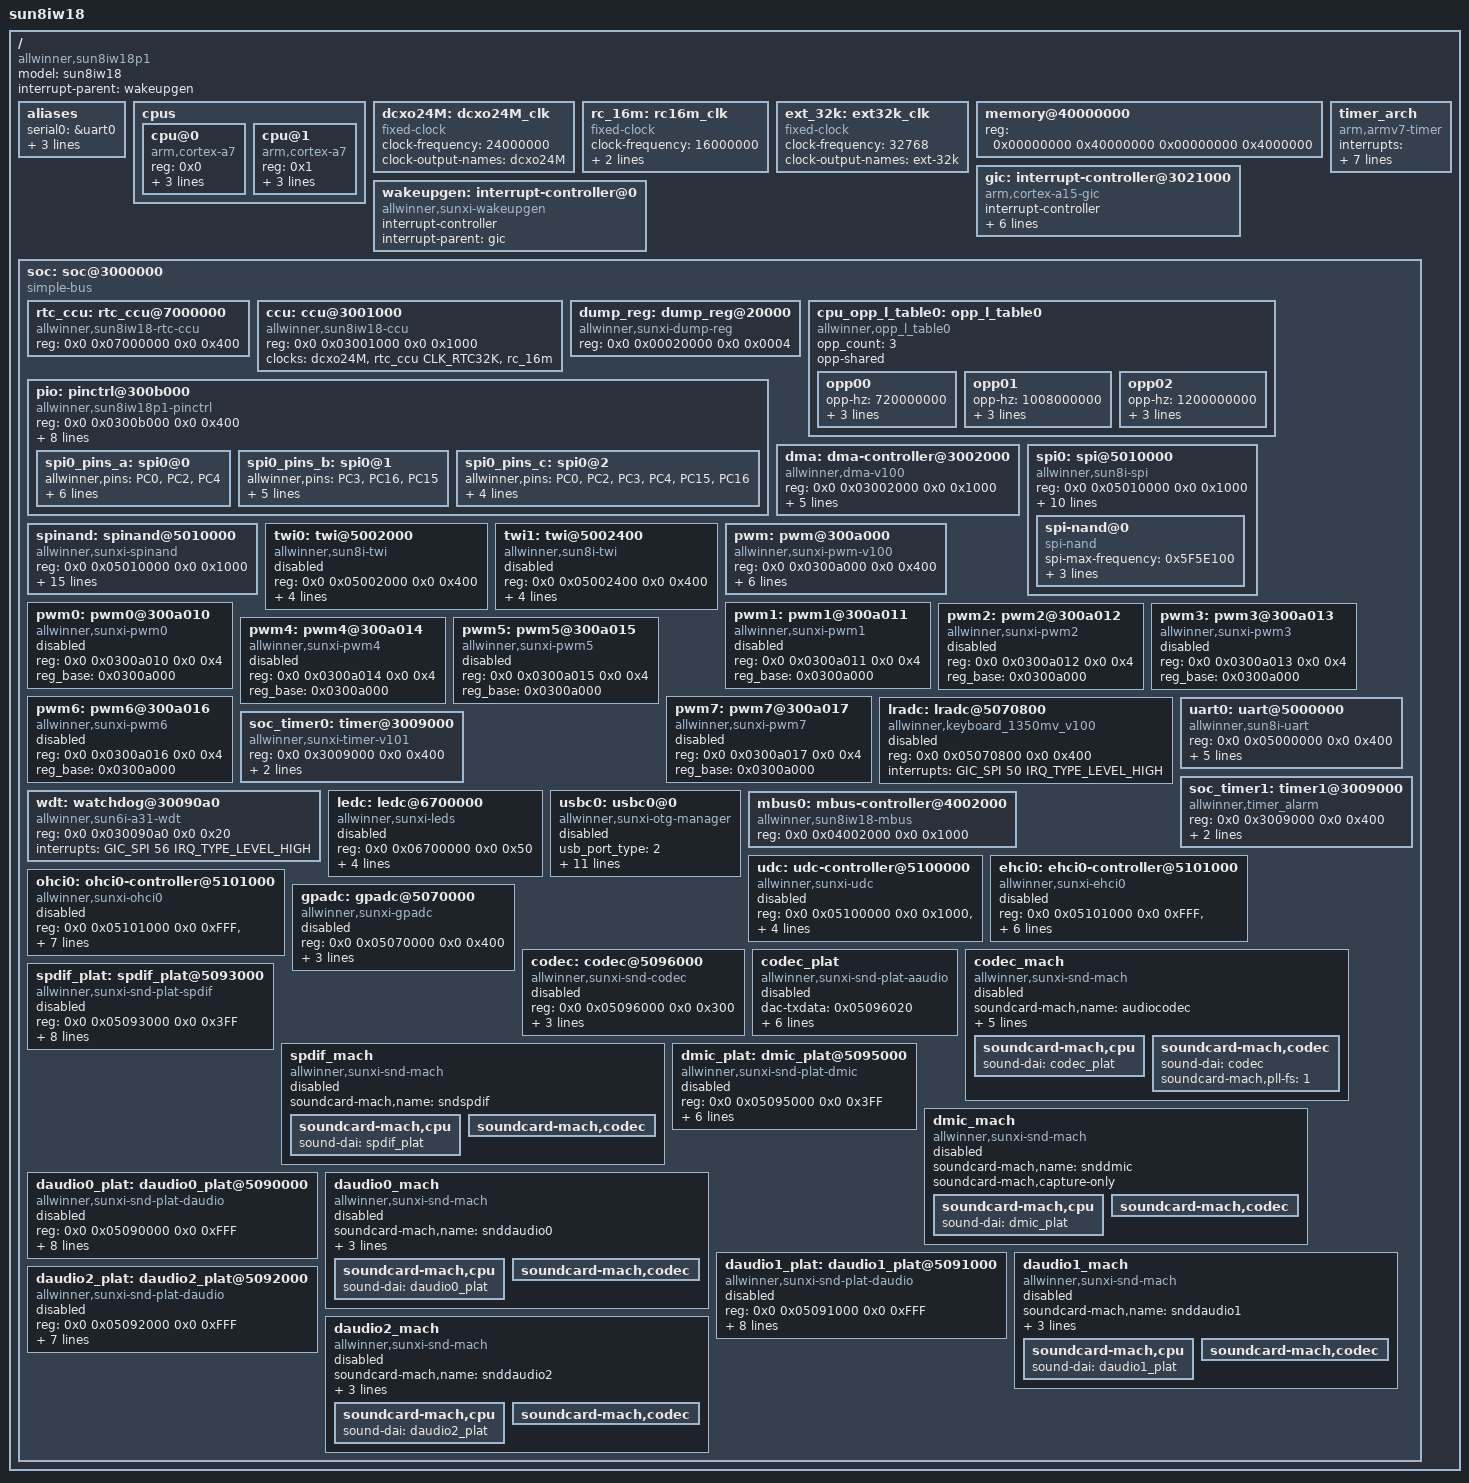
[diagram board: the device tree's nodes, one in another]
/*
 * Allwinner Technology CO., Ltd. sun8iw18p1 platform
 *
 * modify base on juno.dts
 */

/* optee used 4M: SHM 1M, OS 1M, TA 6M*/
/memreserve/ 0x41800000 0x00800000;

#include <dt-bindings/interrupt-controller/arm-gic.h>
#include <dt-bindings/gpio/gpio.h>
#include <dt-bindings/gpio/sun4i-gpio.h>
#include <dt-bindings/clock/sun8iw18-ccu.h>
#include <dt-bindings/reset/sun8iw18-ccu.h>
#include <dt-bindings/clock/sun8iw18-rtc.h>

/ {
	model = "sun8iw18";
	compatible = "allwinner,sun8iw18p1";
	interrupt-parent = <&wakeupgen>;
	#address-cells = <2>;
	#size-cells = <2>;

	aliases {
		serial0 = &uart0;
		pio = &pio;
		spi0 = &spi0;
		spinand = &spinand;
	};

	cpus {
		#address-cells = <1>;
		#size-cells = <0>;

		cpu@0 {
			device_type = "cpu";
			compatible = "arm,cortex-a7","arm,armv7";
			reg = <0x0>;
			enable-method = "psci";
			clocks = <&ccu CLK_CPUX>;
			clock-names = "cpu";
			operating-points-v2 = <&cpu_opp_l_table0>;
		};

		cpu@1 {
			device_type = "cpu";
			compatible = "arm,cortex-a7","arm,armv7";
			reg = <0x1>;
			enable-method = "psci";
			clocks = <&ccu CLK_CPUX>;
			clock-names = "cpu";
			operating-points-v2 = <&cpu_opp_l_table0>;
		};
	};

	dcxo24M: dcxo24M_clk {
		#clock-cells = <0>;
		compatible = "fixed-clock";
		clock-frequency = <24000000>;
		clock-output-names = "dcxo24M";
	};

	rc_16m: rc16m_clk {
		#clock-cells = <0>;
		compatible = "fixed-clock";
		clock-frequency = <16000000>;
		clock-accuracy = <300000000>;
		clock-output-names = "rc-16m";
	};

	ext_32k: ext32k_clk {
		#clock-cells = <0>;
		compatible = "fixed-clock";
		clock-frequency = <32768>;
		clock-output-names = "ext-32k";
	};

	memory@40000000 {
		device_type = "memory";
		reg = <0x00000000 0x40000000 0x00000000 0x4000000>;
	};

	gic: interrupt-controller@3021000 {
		compatible = "arm,cortex-a15-gic", "arm,cortex-a9-gic";
		#interrupt-cells = <3>;
		#address-cells = <0>;
		device_type = "gic";
		interrupt-controller;
		reg = <0x0 0x03021000 0 0x1000>, /* GIC Dist */
		      <0x0 0x03022000 0 0x2000>, /* GIC CPU */
		      <0x0 0x03024000 0 0x2000>, /* GIC VCPU Control */
		      <0x0 0x03026000 0 0x2000>; /* GIC VCPU */
		interrupts = <GIC_PPI 9 0xf04>; /* GIC Maintenence IRQ */
		interrupt-parent = <&gic>;
	};

	wakeupgen: interrupt-controller@0 {
		compatible = "allwinner,sunxi-wakeupgen";
		interrupt-controller;
		#interrupt-cells = <3>;
		interrupt-parent = <&gic>;
	};

	timer_arch {
		compatible = "arm,armv7-timer";
		interrupts = <GIC_PPI 13 (GIC_CPU_MASK_SIMPLE(4) | IRQ_TYPE_LEVEL_LOW)>,
					<GIC_PPI 14 (GIC_CPU_MASK_SIMPLE(4) | IRQ_TYPE_LEVEL_LOW)>,
					<GIC_PPI 11 (GIC_CPU_MASK_SIMPLE(4) | IRQ_TYPE_LEVEL_LOW)>,
					<GIC_PPI 10 (GIC_CPU_MASK_SIMPLE(4) | IRQ_TYPE_LEVEL_LOW)>;
		clock-frequency = <24000000>;
		arm,cpu-registers-not-fw-configured;
		interrupt-parent = <&gic>;
	};

	soc: soc@3000000 {
		compatible = "simple-bus";
		#address-cells = <2>;
		#size-cells = <2>;
		ranges;
		device_type = "soc";

		rtc_ccu: rtc_ccu@7000000 {
			compatible = "allwinner,sun8iw18-rtc-ccu";
			reg = <0x0 0x07000000 0x0 0x400>;
			#clock-cells = <1>;
			#reset-cells = <1>;
		};

		ccu: ccu@3001000 {
			compatible = "allwinner,sun8iw18-ccu";
			reg = <0x0 0x03001000 0x0 0x1000>;
			clocks = <&dcxo24M>, <&rtc_ccu CLK_RTC32K>, <&rc_16m>;
			clock-names = "hosc", "losc", "iosc";
			#clock-cells = <1>;
			#reset-cells = <1>;
		};

		dump_reg: dump_reg@20000 {
			compatible = "allwinner,sunxi-dump-reg";
			reg = <0x0 0x00020000 0x0 0x0004>;
		};

		cpu_opp_l_table0: opp_l_table0 {
			/* compatible = "operating-points-v2"; */
			compatible = "allwinner,opp_l_table0";
			opp_count = <3>;
			opp-shared;

			opp00 {
				opp-hz = /bits/ 64 <720000000>;
				opp-microvolt = <820000>;
				axi-bus-divide-ratio = <3>;
				clock-latency-ns = <2000000>;
			};

			opp01 {
				opp-hz = /bits/ 64 <1008000000>;
				opp-microvolt = <900000>;
				axi-bus-divide-ratio = <3>;
				clock-latency-ns = <2000000>;
			};

			opp02 {
				opp-hz = /bits/ 64 <1200000000>;
				opp-microvolt = <1000000>;
				axi-bus-divide-ratio = <3>;
				clock-latency-ns = <2000000>;
			};

		};
		pio: pinctrl@300b000 {
			compatible = "allwinner,sun8iw18p1-pinctrl";
			reg = <0x0 0x0300b000 0x0 0x400>;
			interrupts = <GIC_SPI 43 IRQ_TYPE_LEVEL_HIGH>,
				     <GIC_SPI 44 IRQ_TYPE_LEVEL_HIGH>,
				     <GIC_SPI 46 IRQ_TYPE_LEVEL_HIGH>,
				     <GIC_SPI 47 IRQ_TYPE_LEVEL_HIGH>;
			device_type = "pio";
			clocks = <&ccu CLK_APB1>, <&dcxo24M>, <&rtc_ccu CLK_RTC32K>;
			clock-names = "apb", "hosc", "bus";
			gpio-controller;
			interrupt-controller;
			#interrupt-cells = <3>;
			#size-cells = <0>;
			#gpio-cells = <3>;

			spi0_pins_a: spi0@0 {
				allwinner,pins = "PC0", "PC2", "PC4";
				allwinner,pname = "spi0_sclk", "spi0_mosi",
						  "spi0_miso";
				allwinner,function = "spi0";
				allwinner,muxsel = <4>;
				allwinner,drive = <1>;
				allwinner,pull = <0>;
			};

			spi0_pins_b: spi0@1 {
				allwinner,pins = "PC3", "PC16", "PC15";
				allwinner,pname = "spi0_cs0", "spi0_hold",
						  "spi0_wp";
				allwinner,function = "spi0";
				allwinner,muxsel = <4>;
				allwinner,drive = <1>;
				allwinner,pull = <1>; 	// only CS should be pulled up
			};

			spi0_pins_c: spi0@2 {
				allwinner,pins = "PC0", "PC2", "PC3", "PC4",
						 "PC15", "PC16";
				allwinner,function = "io_disabled";
				allwinner,muxsel = <7>;
				allwinner,drive = <1>;
				allwinner,pull = <0>;
			};


		};

		dma:dma-controller@3002000 {
			compatible = "allwinner,dma-v100";
			reg = <0x0 0x03002000 0x0 0x1000>;
			interrupts = <GIC_SPI 34 IRQ_TYPE_LEVEL_HIGH>;
			clocks = <&ccu CLK_BUS_DMA>, <&ccu CLK_MBUS_DMA>;
			clock-names = "bus", "mbus";
			resets = <&ccu RST_BUS_DMA>;
			dma-channels = <10>;
			dma-requests = <47>;
			#dma-cells = <1>;
		};

		spi0: spi@5010000 {
			#address-cells = <1>;
			#size-cells = <0>;
			compatible = "allwinner,sun8i-spi";
			device_type = "spi0";
			reg = <0x0 0x05010000 0x0 0x1000>;
			interrupts = <GIC_SPI 81 IRQ_TYPE_LEVEL_HIGH>;
			clocks = <&ccu CLK_PLL_PERI0_1X>, <&ccu CLK_SPI0>, <&ccu CLK_BUS_SPI0>;
			clock-names = "pll", "mod", "bus";
			resets = <&ccu RST_BUS_SPI0>;
			clock-frequency = <100000000>;
			pinctrl-names = "default", "sleep";
			pinctrl-0 = <&spi0_pins_a &spi0_pins_b>;
			pinctrl-1 = <&spi0_pins_c>;
			spi0_cs_number = <2>;
			spi0_cs_bitmap = <3>;
                        dmas = <&dma 22>, <&dma 22>;
			dma-names = "tx", "rx";
			status = "okay";
			spi-nand@0 {
				compatible = "spi-nand";
				spi-max-frequency=<0x5F5E100>;
				reg = <0x0>;
				spi-rx-bus-width=<0x02>;
				spi-tx-bus-width=<0x01>;
				status = "okay";
			};
		};

		spinand: spinand@5010000 {
			compatible = "allwinner,sunxi-spinand", "allwinner,sunxi-mtd-spinand";
			device_type = "spinand";
			reg = <0x0 0x05010000 0x0 0x1000>;
			interrupts = <GIC_SPI 81 IRQ_TYPE_LEVEL_HIGH>;
			clocks = <&ccu CLK_PLL_PERI0_1X>, <&ccu CLK_SPI0>;
			pinctrl-names = "default", "sleep";
			pinctrl-0 = <&spi0_pins_a &spi0_pins_b>;
			pinctrl-1 = <&spi0_pins_c>;
			nand0_regulator1 = "vcc-nand";
			nand0_regulator2 = "none";
			nand0_cache_level = <0x55aaaa55>;
			nand0_flush_cache_num = <0x55aaaa55>;
			nand0_capacity_level = <0x55aaaa55>;
			nand0_id_number_ctl = <0x55aaaa55>;
			nand0_print_level = <0x55aaaa55>;
			nand0_p0 = <0x55aaaa55>;
			nand0_p1 = <0x55aaaa55>;
			nand0_p2 = <0x55aaaa55>;
			nand0_p3 = <0x55aaaa55>;
			status = "okay";
		};

		twi0: twi@5002000 {
			#address-cells = <1>;
			#size-cells = <0>;
			compatible = "allwinner,sun8i-twi";
			device_type = "twi0";
			reg = <0x0 0x05002000 0x0 0x400>;
			interrupts = <GIC_SPI 70 IRQ_TYPE_LEVEL_HIGH>;
			clocks = <&ccu CLK_TWI0>;
			clock-names = "bus";
			resets = <&ccu RST_BUS_TWI0>;
			dmas = <&dma 45>, <&dma 45>;
			dma-names = "tx", "rx";
			status = "disabled";
		};

		twi1: twi@5002400 {
			#address-cells = <1>;
			#size-cells = <0>;
			compatible = "allwinner,sun8i-twi";
			device_type = "twi1";
			reg = <0x0 0x05002400 0x0 0x400>;
			interrupts = <GIC_SPI 71 IRQ_TYPE_LEVEL_HIGH>;
			clocks = <&ccu CLK_TWI1>;
			clock-names = "bus";
			resets = <&ccu RST_BUS_TWI1>;
			dmas = <&dma 46>, <&dma 46>;
			dma-names = "tx", "rx";
			status = "disabled";
		};

		pwm: pwm@300a000 {
			#pwm-cells = <0x3>;
			compatible = "allwinner,sunxi-pwm-v100";
			reg = <0x0 0x0300a000 0x0 0x400>;
			clocks = <&ccu CLK_PWM>;
			resets = <&ccu RST_BUS_PWM>;
			pwm-number = <8>;
			pwm-base = <0x0>;
			sunxi-pwms = <&pwm0>, <&pwm1>, <&pwm2>, <&pwm3>, <&pwm4>,
			       <&pwm5>, <&pwm6>, <&pwm7>;
		};

		pwm0: pwm0@300a010 {
			compatible = "allwinner,sunxi-pwm0";
			reg = <0x0 0x0300a010 0x0 0x4>;
			reg_base = <0x0300a000>;
			status = "disabled";
		};

		pwm1: pwm1@300a011 {
			compatible = "allwinner,sunxi-pwm1";
			reg = <0x0 0x0300a011 0x0 0x4>;
			reg_base = <0x0300a000>;
			status = "disabled";
		};

		pwm2: pwm2@300a012 {
			compatible = "allwinner,sunxi-pwm2";
			reg = <0x0 0x0300a012 0x0 0x4>;
			reg_base = <0x0300a000>;
			status = "disabled";
		};

		pwm3: pwm3@300a013 {
			compatible = "allwinner,sunxi-pwm3";
			reg = <0x0 0x0300a013 0x0 0x4>;
			reg_base = <0x0300a000>;
			status = "disabled";
		};

		pwm4: pwm4@300a014 {
			compatible = "allwinner,sunxi-pwm4";
			reg = <0x0 0x0300a014 0x0 0x4>;
			reg_base = <0x0300a000>;
			status = "disabled";
		};

		pwm5: pwm5@300a015 {
			compatible = "allwinner,sunxi-pwm5";
			reg = <0x0 0x0300a015 0x0 0x4>;
			reg_base = <0x0300a000>;
			status = "disabled";
		};

		pwm6: pwm6@300a016 {
			compatible = "allwinner,sunxi-pwm6";
			reg = <0x0 0x0300a016 0x0 0x4>;
			reg_base = <0x0300a000>;
			status = "disabled";
		};

		pwm7: pwm7@300a017 {
			compatible = "allwinner,sunxi-pwm7";
			reg = <0x0 0x0300a017 0x0 0x4>;
			reg_base = <0x0300a000>;
			status = "disabled";
		};

		lradc: lradc@5070800 {
			compatible = "allwinner,keyboard_1350mv_v100";
			reg = <0x0 0x05070800 0x0 0x400>;
			interrupts = <GIC_SPI 50 IRQ_TYPE_LEVEL_HIGH>;
			status = "disabled";
		};

		uart0: uart@5000000 {
			compatible = "allwinner,sun8i-uart";
			device_type = "uart0";
			reg = <0x0 0x05000000 0x0 0x400>;
			interrupts = <GIC_SPI 76 IRQ_TYPE_LEVEL_HIGH>;
			clocks = <&ccu CLK_BUS_UART0>;
			resets = <&ccu RST_BUS_UART0>;
			uart0_port = <0>;
			uart0_type = <2>;
			status = "okay";
		};

		soc_timer0: timer@3009000 {
			compatible = "allwinner,sunxi-timer-v101";
			device_type = "soc_timer";
			reg = <0x0 0x3009000 0x0 0x400>;
			interrupts = <GIC_SPI 85 IRQ_TYPE_LEVEL_HIGH>;
			clocks = <&dcxo24M>, <&ccu CLK_RTC32K>;
		};

		soc_timer1: timer1@3009000 {
			compatible = "allwinner,timer_alarm";
			reg = <0x0 0x3009000 0x0 0x400>;
			interrupts = <GIC_SPI 86 IRQ_TYPE_LEVEL_HIGH>;
			wakeup-source;
			status = "okay";
		};

		wdt: watchdog@30090a0 {
			compatible = "allwinner,sun6i-a31-wdt";
			reg = <0x0 0x030090a0 0x0 0x20>;
			interrupts = <GIC_SPI 56 IRQ_TYPE_LEVEL_HIGH>;
			status = "okay";
		};

		ledc: ledc@6700000 {
			#address-cells = <1>;
			#size-cells = <0>;
			compatible = "allwinner,sunxi-leds";
			reg = <0x0 0x06700000 0x0 0x50>;
			interrupts = <GIC_SPI 60 IRQ_TYPE_LEVEL_HIGH>;
			interrupt-names = "ledcirq";
			clocks = <&ccu CLK_LEDC>, <&ccu CLK_BUS_LEDC>;
			clock-names = "clk_ledc", "clk_cpuapb";
			resets = <&ccu RST_BUS_LEDC>;
			reset-names = "ledc_reset";
			dmas = <&dma 43>, <&dma 43>;
			dma-names = "rx", "tx";
			status = "disabled";
		};

		usbc0:usbc0@0 {
			device_type = "usbc0";
			compatible = "allwinner,sunxi-otg-manager";
			usb_port_type = <2>;
			usb_detect_type = <1>;
			usb_detect_mode = <0>;
			usb_id_gpio;
			usb_det_vbus_gpio;
			usb_drv_vbus_gpio;
			usb_regulator_io = "nocare";
			usb_wakeup_suspend = <0>;
			usb_luns = <3>;
			usb_serial_unique = <0>;
			usb_serial_number = "20080411";
			rndis_wceis = <1>;
			status = "disabled";
		};

		mbus0: mbus-controller@4002000 {
			compatible = "allwinner,sun8iw18-mbus";
			reg = <0x0 0x04002000 0x0 0x1000>;
			#mbus-cells = <1>;
			status = "okay";
		};

		udc:udc-controller@5100000 {
			compatible = "allwinner,sunxi-udc";
			reg = <0x0 0x05100000 0x0 0x1000>, /*udc base*/
			      <0x0 0x00000000 0x0 0x100>; /*sram base*/
			interrupts = <GIC_SPI 37 IRQ_TYPE_LEVEL_HIGH>;
			clocks = <&ccu CLK_USBOTG>, <&ccu CLK_USBPHY0>;
			clock-names = "bus_otg", "phy";
			resets = <&ccu RST_USB_OTG>, <&ccu RST_USB_PHY0>;
			reset-names = "otg", "phy";
			status = "disabled";
		};

		ehci0:ehci0-controller@5101000 {
			compatible = "allwinner,sunxi-ehci0";
			reg = <0x0 0x05101000 0x0 0xFFF>, /*hci0 base*/
			      <0x0 0x00000000 0x0 0x100>, /*sram base*/
			      <0x0 0x05100000 0x0 0x1000>; /*otg base*/
			interrupts = <GIC_SPI 38 IRQ_TYPE_LEVEL_HIGH>;
			clocks = <&ccu CLK_USBEHCI0>, <&ccu CLK_USBPHY0>;
			clock-names = "bus_hci", "phy";
			resets = <&ccu RST_USB_EHCI0>, <&ccu RST_USB_PHY0>;
			reset-names = "hci", "phy";
			hci_ctrl_no = <0>;
			status = "disabled";
		};

		ohci0:ohci0-controller@5101000 {
			compatible = "allwinner,sunxi-ohci0";
			reg = <0x0 0x05101000 0x0 0xFFF>, /*hci0 base*/
			      <0x0 0x00000000 0x0 0x100>, /*sram base*/
			      <0x0 0x05100000 0x0 0x1000>; /*otg base*/
			interrupts = <GIC_SPI 39 IRQ_TYPE_LEVEL_HIGH>;
			clocks = <&ccu CLK_USBOHCI0>, <&ccu CLK_USB0>, <&ccu CLK_USBPHY0>;
			clock-names = "bus_hci", "ohci", "phy";
			resets = <&ccu RST_USB_OHCI0>, <&ccu RST_USB_PHY0>;
			reset-names = "hci", "phy";
			hci_ctrl_no = <0>;
			status = "disabled";
		};

		gpadc: gpadc@5070000 {
			compatible = "allwinner,sunxi-gpadc";
			reg = <0x0 0x05070000 0x0 0x400>;
			interrupts = <GIC_SPI 48 IRQ_TYPE_LEVEL_HIGH>;
			clocks = <&ccu CLK_BUS_GPADC>;
			clock-names = "bus";
			resets = <&ccu RST_BUS_GPADC>;
			status = "disabled";
		};

		/* audio driver ----- audio codec*/
		codec:codec@5096000 {
			#sound-dai-cells = <0>;
			compatible	= "allwinner,sunxi-snd-codec";
			reg		= <0x0 0x05096000 0x0 0x300>;
			resets		= <&ccu RST_BUS_AUDIO_CODEC>;
			clocks		= <&ccu CLK_PLL_AUDIO0_4X>,
					  <&ccu CLK_AUDIO_CODEC>,
					  <&ccu CLK_AUDIO_CODEC_1X>;
			clock-names	= "clk_pll_audio_4x",
					  "clk_bus_audio",
					  "clk_audio_1x";
			status = "disabled";
		};

		codec_plat:codec_plat {
			#sound-dai-cells = <0>;
			compatible	= "allwinner,sunxi-snd-plat-aaudio";
			dac-txdata	= <0x05096020>;
			adc-txdata	= <0x05096040>;
			dmas		= <&dma 6>, <&dma 6>;
			dma-names	= "tx", "rx";
			playback-cma	= <128>;
			capture-cma	= <128>;
			tx-fifo-size	= <128>;
			rx-fifo-size	= <128>;
			status = "disabled";
		};

		codec_mach:codec_mach {
			compatible = "allwinner,sunxi-snd-mach";
			soundcard-mach,name		= "audiocodec";
			soundcard-mach,pin-switches	= "MIC1", "MIC2", "MIC3",
							  "LINEOUT", "SPK";
			soundcard-mach,routing		= "MIC1_PIN",	"MIC1",
							  "MIC2_PIN",	"MIC2",
							  "MIC3_PIN",	"MIC3",
							  "LINEOUT",	"LINEOUT_PIN",
							  "SPK",	"LINEOUT_PIN";
			status = "disabled";
			soundcard-mach,cpu {
				sound-dai = <&codec_plat>;
			};
			soundcard-mach,codec {
				sound-dai = <&codec>;
				soundcard-mach,pll-fs	= <1>;
			};
		};

		/* audio dirver module -> spdif */
		spdif_plat:spdif_plat@5093000 {
			#sound-dai-cells = <0>;
			compatible	= "allwinner,sunxi-snd-plat-spdif";
			reg		= <0x0 0x05093000 0x0 0x3FF>;
			resets		= <&ccu RST_BUS_SPDIF>;
			clocks		= <&ccu CLK_PLL_AUDIO0_4X>,
					  <&ccu CLK_SPDIF>,
					  <&ccu CLK_BUS_SPDIF>;
			clock-names	= "clk_pll_audio_4x",
					  "clk_spdif",
					  "clk_bus_spdif";
			dmas		= <&dma 2>, <&dma 2>;
			dma-names	= "tx", "rx";
			playback-cma	= <128>;
			capture-cma	= <128>;
			tx-fifo-size	= <128>;
			rx-fifo-size	= <128>;
			status = "disabled";
		};

		spdif_mach:spdif_mach {
			compatible = "allwinner,sunxi-snd-mach";
			soundcard-mach,name = "sndspdif";
			status = "disabled";
			soundcard-mach,cpu {
				sound-dai = <&spdif_plat>;
			};
			soundcard-mach,codec {
			};
		};

		/* audio dirver module -> dmic */
		dmic_plat:dmic_plat@5095000 {
			#sound-dai-cells = <0>;
			compatible	= "allwinner,sunxi-snd-plat-dmic";
			reg		= <0x0 0x05095000 0x0 0x3FF>;
			resets		= <&ccu RST_BUS_DMIC>;
			clocks		= <&ccu CLK_PLL_AUDIO0_4X>,
					  <&ccu CLK_BUS_DMIC>,
					  <&ccu CLK_DMIC>;
			clock-names	= "clk_pll_audio_4x",
					  "clk_bus_dmic",
					  "clk_dmic";
			dmas		= <&dma 7>;
			dma-names	= "rx";
			capture-cma	= <128>;
			rx-fifo-size	= <128>;
			status = "disabled";
		};

		dmic_mach:dmic_mach{
			compatible = "allwinner,sunxi-snd-mach";
			soundcard-mach,name		= "snddmic";
			soundcard-mach,capture-only;
			status = "disabled";
			soundcard-mach,cpu {
				sound-dai = <&dmic_plat>;
			};
			soundcard-mach,codec {
			};
		};

		/* audio dirver module -> I2S/PCM */
		daudio0_plat:daudio0_plat@5090000 {
			#sound-dai-cells = <0>;
			compatible = "allwinner,sunxi-snd-plat-daudio";
			reg		= <0x0 0x05090000 0x0 0xFFF>;
			resets		= <&ccu RST_BUS_I2S_PCM0>;
			clocks		= <&ccu CLK_PLL_AUDIO0_4X>,
					  <&ccu CLK_I2S_PCM0>,
					  <&ccu CLK_BUS_I2S_PCM0>;
			clock-names	= "clk_pll_audio_4x",
					  "clk_i2s",
					  "clk_bus_i2s";
			dmas		= <&dma 3>, <&dma 3>;
			dma-names	= "tx", "rx";
			playback-cma	= <128>;
			capture-cma	= <128>;
			tx-fifo-size	= <128>;
			rx-fifo-size	= <128>;
			status = "disabled";
		};

		daudio0_mach:daudio0_mach{
			compatible = "allwinner,sunxi-snd-mach";
			soundcard-mach,name		= "snddaudio0";
			soundcard-mach,format		= "i2s";
			soundcard-mach,slot-num		= <2>;
			soundcard-mach,slot-width	= <32>;
			status = "disabled";
			soundcard-mach,cpu {
				sound-dai = <&daudio0_plat>;
			};
			soundcard-mach,codec {
			};
		};

		daudio1_plat:daudio1_plat@5091000 {
			#sound-dai-cells = <0>;
			compatible = "allwinner,sunxi-snd-plat-daudio";
			reg		= <0x0 0x05091000 0x0 0xFFF>;
			resets		= <&ccu RST_BUS_I2S_PCM1>;
			clocks		= <&ccu CLK_PLL_AUDIO0_4X>,
					  <&ccu CLK_I2S_PCM1>,
					  <&ccu CLK_BUS_I2S_PCM1>;
			clock-names	= "clk_pll_audio_4x",
					  "clk_i2s",
					  "clk_bus_i2s";
			dmas		= <&dma 4>, <&dma 4>;
			dma-names	= "tx", "rx";
			playback-cma	= <128>;
			capture-cma	= <128>;
			tx-fifo-size	= <128>;
			rx-fifo-size	= <128>;
			status = "disabled";
		};

		daudio1_mach:daudio1_mach{
			compatible = "allwinner,sunxi-snd-mach";
			soundcard-mach,name		= "snddaudio1";
			soundcard-mach,format		= "i2s";
			soundcard-mach,slot-num		= <2>;
			soundcard-mach,slot-width	= <32>;
			status = "disabled";
			soundcard-mach,cpu {
				sound-dai = <&daudio1_plat>;
			};
			soundcard-mach,codec {
			};
		};

		daudio2_plat:daudio2_plat@5092000 {
			#sound-dai-cells = <0>;
			compatible = "allwinner,sunxi-snd-plat-daudio";
			reg		= <0x0 0x05092000 0x0 0xFFF>;
			resets		= <&ccu RST_BUS_I2S_PCM2>;
			clocks		= <&ccu CLK_PLL_AUDIO0_4X>,
					  <&ccu CLK_I2S_PCM2>,
					  <&ccu CLK_BUS_I2S_PCM2>;
			clock-names	= "clk_pll_audio_4x",
					  "clk_i2s",
					  "clk_bus_i2s";
			/* dmas		= <&dma 5>, <&dma 5>;
			dma-names	= "tx", "rx"; */
			playback-cma	= <128>;
			capture-cma	= <128>;
			tx-fifo-size	= <128>;
			rx-fifo-size	= <128>;
			status = "disabled";
		};

		daudio2_mach:daudio2_mach{
			compatible = "allwinner,sunxi-snd-mach";
			soundcard-mach,name		= "snddaudio2";
			soundcard-mach,format		= "i2s";
			soundcard-mach,slot-num		= <2>;
			soundcard-mach,slot-width	= <32>;
			status = "disabled";
			soundcard-mach,cpu {
				sound-dai = <&daudio2_plat>;
			};
			soundcard-mach,codec {
			};
		};
		/* audio dirver module -> END */

	};
};
